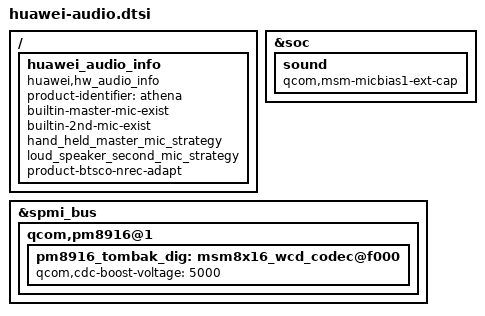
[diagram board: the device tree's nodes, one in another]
/* < DTS2015072404956 goupeipei 20150724 begin */
/* < DTS2014121300528 sujunfeng 20141213 begin */
/* < DTS2015010903303 yubin 20150109 begin */
/* < DTS2015011509397 yubin 20150115 begin */
/* < DTS2015052707098 huangwei/wx223581 20150527 begin */
/ {
    huawei_audio_info {
        compatible = "huawei,hw_audio_info";
        product-identifier = "athena";
        builtin-master-mic-exist;
        builtin-2nd-mic-exist;
        hand_held_master_mic_strategy;
        status = "ok";
        loud_speaker_second_mic_strategy;
        product-btsco-nrec-adapt;
    };
};
&soc {
    sound {
        qcom,msm-micbias1-ext-cap;
    };
};
&spmi_bus {
        qcom,pm8916@1 {
                pm8916_tombak_dig: msm8x16_wcd_codec@f000{
                        qcom,cdc-boost-voltage = <5000>;
                };
        };
};
/* DTS2015052707098 huangwei/wx223581 20150527 end > */
/* DTS2015011509397 yubin 20150115 end > */
/* DTS2015010903303 yubin 20150109 end > */
/* DTS2014121300528 sujunfeng 20141213 end > */
/* DTS2015072404956 goupeipei 20150724 end > */
